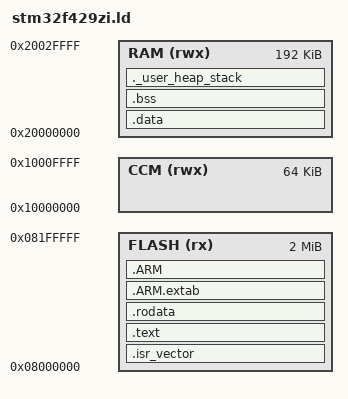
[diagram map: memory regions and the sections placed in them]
/* stm32f429zi.ld — STM32F429ZIT6 memory map.
 * 2 MB Flash + 256 KB SRAM (192K main + 64K aux) + 64 KB CCM RAM.
 * RM0090 §3 + datasheet DS9405 Table 7.
 */
ENTRY(Reset_Handler)

MEMORY
{
    FLASH (rx)   : ORIGIN = 0x08000000, LENGTH = 2048K
    RAM   (rwx)  : ORIGIN = 0x20000000, LENGTH = 192K
    CCM   (rwx)  : ORIGIN = 0x10000000, LENGTH = 64K
}

_estack = ORIGIN(RAM) + LENGTH(RAM);   /* main stack at top of SRAM */
_Min_Heap_Size = 0x200;
_Min_Stack_Size = 0x800;

SECTIONS
{
    .isr_vector :
    {
        . = ALIGN(4);
        KEEP(*(.isr_vector))
        . = ALIGN(4);
    } >FLASH

    .text :
    {
        . = ALIGN(4);
        *(.text)
        *(.text*)
        *(.glue_7)
        *(.glue_7t)
        *(.eh_frame)
        KEEP (*(.init))
        KEEP (*(.fini))
        . = ALIGN(4);
        _etext = .;
    } >FLASH

    .rodata :
    {
        . = ALIGN(4);
        *(.rodata)
        *(.rodata*)
        . = ALIGN(4);
    } >FLASH

    .ARM.extab :
    {
        *(.ARM.extab* .gnu.linkonce.armextab.*)
    } >FLASH

    .ARM :
    {
        __exidx_start = .;
        *(.ARM.exidx*)
        __exidx_end = .;
    } >FLASH

    _sidata = LOADADDR(.data);

    .data : AT (_sidata)
    {
        . = ALIGN(4);
        _sdata = .;
        *(.data)
        *(.data*)
        . = ALIGN(4);
        _edata = .;
    } >RAM

    .bss :
    {
        . = ALIGN(4);
        _sbss = .;
        __bss_start__ = _sbss;
        *(.bss)
        *(.bss*)
        *(COMMON)
        . = ALIGN(4);
        _ebss = .;
        __bss_end__ = _ebss;
    } >RAM

    ._user_heap_stack :
    {
        . = ALIGN(8);
        PROVIDE ( end = . );
        PROVIDE ( _end = . );
        . = . + _Min_Heap_Size;
        . = . + _Min_Stack_Size;
        . = ALIGN(8);
    } >RAM
}
